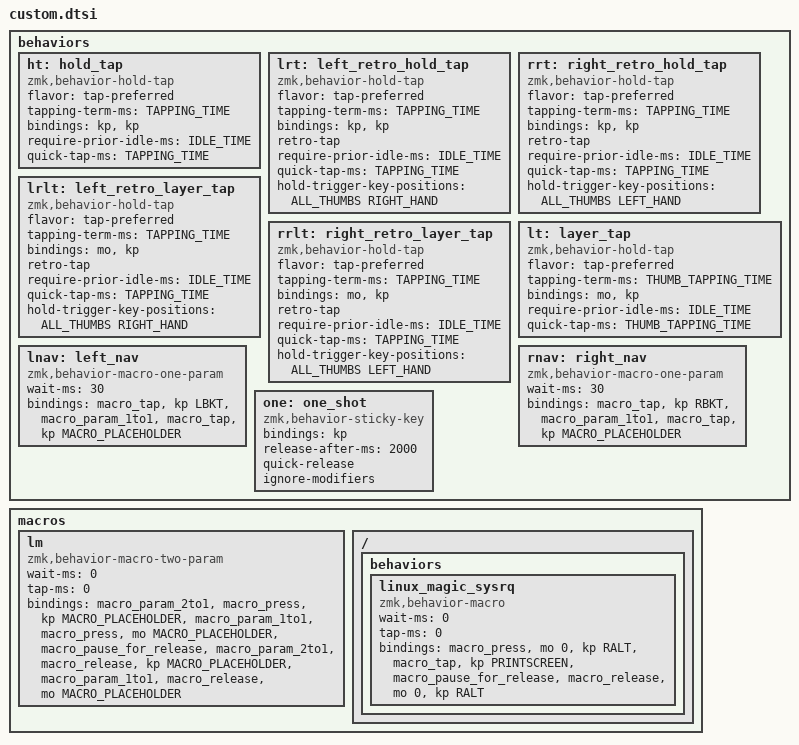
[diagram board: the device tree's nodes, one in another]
#include "hands.h"

#define THUMB_TAPPING_TIME 225
#define TAPPING_TIME 175
#define IDLE_TIME 125


behaviors {

    ht: hold_tap {
        compatible = "zmk,behavior-hold-tap";
        #binding-cells = <2>;
        flavor = "tap-preferred";
        tapping-term-ms = <TAPPING_TIME>;
        bindings = <&kp>, <&kp>;
        require-prior-idle-ms = <IDLE_TIME>;
        quick-tap-ms = <TAPPING_TIME>;
    };

    lrt: left_retro_hold_tap {
        compatible = "zmk,behavior-hold-tap";
        #binding-cells = <2>;
        flavor = "tap-preferred";
        tapping-term-ms = <TAPPING_TIME>;
        bindings = <&kp>, <&kp>;
        retro-tap;
        require-prior-idle-ms = <IDLE_TIME>;
        quick-tap-ms = <TAPPING_TIME>;
        hold-trigger-key-positions = <ALL_THUMBS RIGHT_HAND>;
    };

    rrt: right_retro_hold_tap {
        compatible = "zmk,behavior-hold-tap";
        #binding-cells = <2>;
        flavor = "tap-preferred";
        tapping-term-ms = <TAPPING_TIME>;
        bindings = <&kp>, <&kp>;
        retro-tap;
        require-prior-idle-ms = <IDLE_TIME>;
        quick-tap-ms = <TAPPING_TIME>;
        hold-trigger-key-positions = <ALL_THUMBS LEFT_HAND>;
    };

    lrlt: left_retro_layer_tap {
        compatible = "zmk,behavior-hold-tap";
        #binding-cells = <2>;
        flavor = "tap-preferred";
        tapping-term-ms = <TAPPING_TIME>;
        bindings = <&mo>, <&kp>;
        retro-tap;
        require-prior-idle-ms = <IDLE_TIME>;
        quick-tap-ms = <TAPPING_TIME>;
        hold-trigger-key-positions = <ALL_THUMBS RIGHT_HAND>;
    };

    rrlt: right_retro_layer_tap {
        compatible = "zmk,behavior-hold-tap";
        #binding-cells = <2>;
        flavor = "tap-preferred";
        tapping-term-ms = <TAPPING_TIME>;
        bindings = <&mo>, <&kp>;
        retro-tap;
        require-prior-idle-ms = <IDLE_TIME>;
        quick-tap-ms = <TAPPING_TIME>;
        hold-trigger-key-positions = <ALL_THUMBS LEFT_HAND>;
    };

    lt: layer_tap {
        compatible = "zmk,behavior-hold-tap";
        #binding-cells = <2>;
        flavor = "tap-preferred";
        tapping-term-ms = <THUMB_TAPPING_TIME>;
        bindings = <&mo>, <&kp>;
        require-prior-idle-ms = <IDLE_TIME>;
        quick-tap-ms = <THUMB_TAPPING_TIME>;
    };

    lnav: left_nav {
        compatible = "zmk,behavior-macro-one-param";
        #binding-cells = <1>; // Must be 1
        wait-ms = <30>;
        bindings
        = <&macro_tap &kp LBKT>
        , <&macro_param_1to1>
        , <&macro_tap &kp MACRO_PLACEHOLDER>
        ;
    };

    rnav: right_nav {
        compatible = "zmk,behavior-macro-one-param";
        #binding-cells = <1>; // Must be 1
        wait-ms = <30>;
        bindings
        = <&macro_tap &kp RBKT>
        , <&macro_param_1to1>
        , <&macro_tap &kp MACRO_PLACEHOLDER>
        ;
    };
    
    one: one_shot {
        compatible = "zmk,behavior-sticky-key";
        #binding-cells = <1>;
        bindings = <&kp>;
        release-after-ms = <2000>;
        quick-release;
        ignore-modifiers;
    };

};


macros {

    /**
     * Temporarily switches to a layer (`&mo`) while a modifier is held.
     * Analogous to QMK's `LM()`, using a parameterized macro.
     *
     * Params:
     *  1. Layer to switch to
     *  2. Modifier to press while layer is active
     *
     * Example:
     *  `&lm NUM_LAYER LSHIFT`
     */
    lm: lm {
        compatible = "zmk,behavior-macro-two-param";
        wait-ms = <0>;
        tap-ms = <0>;
        #binding-cells = <2>;
        bindings
            = <&macro_param_2to1>
            , <&macro_press &kp MACRO_PLACEHOLDER>
            , <&macro_param_1to1>
            , <&macro_press &mo MACRO_PLACEHOLDER>
            , <&macro_pause_for_release>
            , <&macro_param_2to1>
            , <&macro_release &kp MACRO_PLACEHOLDER>
            , <&macro_param_1to1>
            , <&macro_release &mo MACRO_PLACEHOLDER>
            ;
    };


    //
    // Linux Magic System Request Key - hold this down and type REISUB
    // - https://www.kernel.org/doc/html/latest/admin-guide/sysrq.html
    // - https://github.com/manna-harbour/miryoku/discussions/259
    //
    ZMK_MACRO(linux_magic_sysrq,
        wait-ms = <0>;
        tap-ms = <0>;
        bindings
            = <&macro_press &mo 0 &kp RALT>
            , <&macro_tap &kp PRINTSCREEN>
            , <&macro_pause_for_release>
            , <&macro_release &mo 0 &kp RALT>
            ;
    )
};

#include "world_base.dtsi"
#include "world_windows.dtsi"
#include "world_macos.dtsi"

